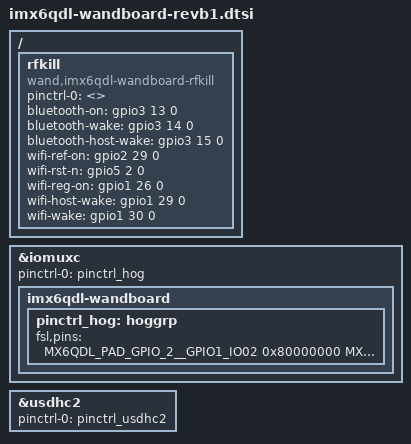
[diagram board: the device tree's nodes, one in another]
// SPDX-License-Identifier: GPL-2.0
//
// Copyright 2013 Freescale Semiconductor, Inc.
//
// Author: Fabio Estevam <fabio.estevam@freescale.com>

#include "imx6qdl-wandboard.dtsi"

/ {
	rfkill {
		compatible = "wand,imx6qdl-wandboard-rfkill";
		pinctrl-names = "default";
		pinctrl-0 = <>;

		bluetooth-on = <&gpio3 13 0>;
		bluetooth-wake = <&gpio3 14 0>;
		bluetooth-host-wake = <&gpio3 15 0>;

		wifi-ref-on = <&gpio2 29 0>;
		wifi-rst-n = <&gpio5 2 0>;
		wifi-reg-on = <&gpio1 26 0>;
		wifi-host-wake = <&gpio1 29 0>;
		wifi-wake = <&gpio1 30 0>;
	};
};

&iomuxc {
	pinctrl-0 = <&pinctrl_hog>;

	imx6qdl-wandboard {
		pinctrl_hog: hoggrp {
			fsl,pins = <
				MX6QDL_PAD_GPIO_2__GPIO1_IO02		0x80000000	/* uSDHC1 CD */
				MX6QDL_PAD_EIM_DA9__GPIO3_IO09		0x80000000	/* uSDHC3 CD */
				MX6QDL_PAD_EIM_EB1__GPIO2_IO29		0x0f0b0		/* WL_REF_ON */
				MX6QDL_PAD_EIM_A25__GPIO5_IO02		0x0f0b0		/* WL_RST_N */
				MX6QDL_PAD_ENET_RXD1__GPIO1_IO26	0x000b0		/* WL_REG_ON */
				MX6QDL_PAD_ENET_TXD1__GPIO1_IO29	0x80000000	/* WL_HOST_WAKE */
				MX6QDL_PAD_ENET_TXD0__GPIO1_IO30	0x80000000	/* WL_WAKE */
				MX6QDL_PAD_EIM_D29__GPIO3_IO29		0x80000000	/* RGMII_nRST */
				MX6QDL_PAD_EIM_DA13__GPIO3_IO13		0x80000000	/* BT_ON */
				MX6QDL_PAD_EIM_DA14__GPIO3_IO14		0x80000000	/* BT_WAKE */
				MX6QDL_PAD_EIM_DA15__GPIO3_IO15		0x80000000	/* BT_HOST_WAKE */
			>;
		};
	};
};

&usdhc2 {
	pinctrl-names = "default";
	pinctrl-0 = <&pinctrl_usdhc2>;
	status = "okay";
};
